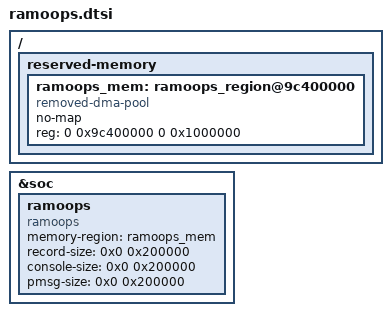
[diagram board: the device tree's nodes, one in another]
/* Copyright (c) 2019, The Linux Foundation. All rights reserved.
 *
 * This program is free software; you can redistribute it and/or modify
 * it under the terms of the GNU General Public License version 2 and
 * only version 2 as published by the Free Software Foundation.
 *
 * This program is distributed in the hope that it will be useful,
 * but WITHOUT ANY WARRANTY; without even the implied warranty of
 * MERCHANTABILITY or FITNESS FOR A PARTICULAR PURPOSE.  See the
 * GNU General Public License for more details.
 */

/ {
	reserved-memory {
		/*
		 * 0xb0000000 is claimed as a device resource by the icnss
		 * (WiFi) node in sdm660.dtsi as its "smmu_iova_ipa" window, so
		 * request_mem_region() for a ramoops region there fails with
		 * -EBUSY and the whole pstore backend never registers.
		 * Place ramoops in the free window between cdsp_fw_mem (ends
		 * 0x95200000) and cont_splash_mem (starts 0x9d400000) instead.
		 */
		ramoops_mem: ramoops_region@9c400000 {
			compatible = "removed-dma-pool";
			no-map;
			reg = <0 0x9c400000 0 0x1000000>;
		};
	};
};

&soc {
	ramoops {
		compatible = "ramoops";
		memory-region = <&ramoops_mem>;
		record-size = <0x0 0x200000>;
		console-size = <0x0 0x200000>;
		pmsg-size = <0x0 0x200000>;
	};
};
